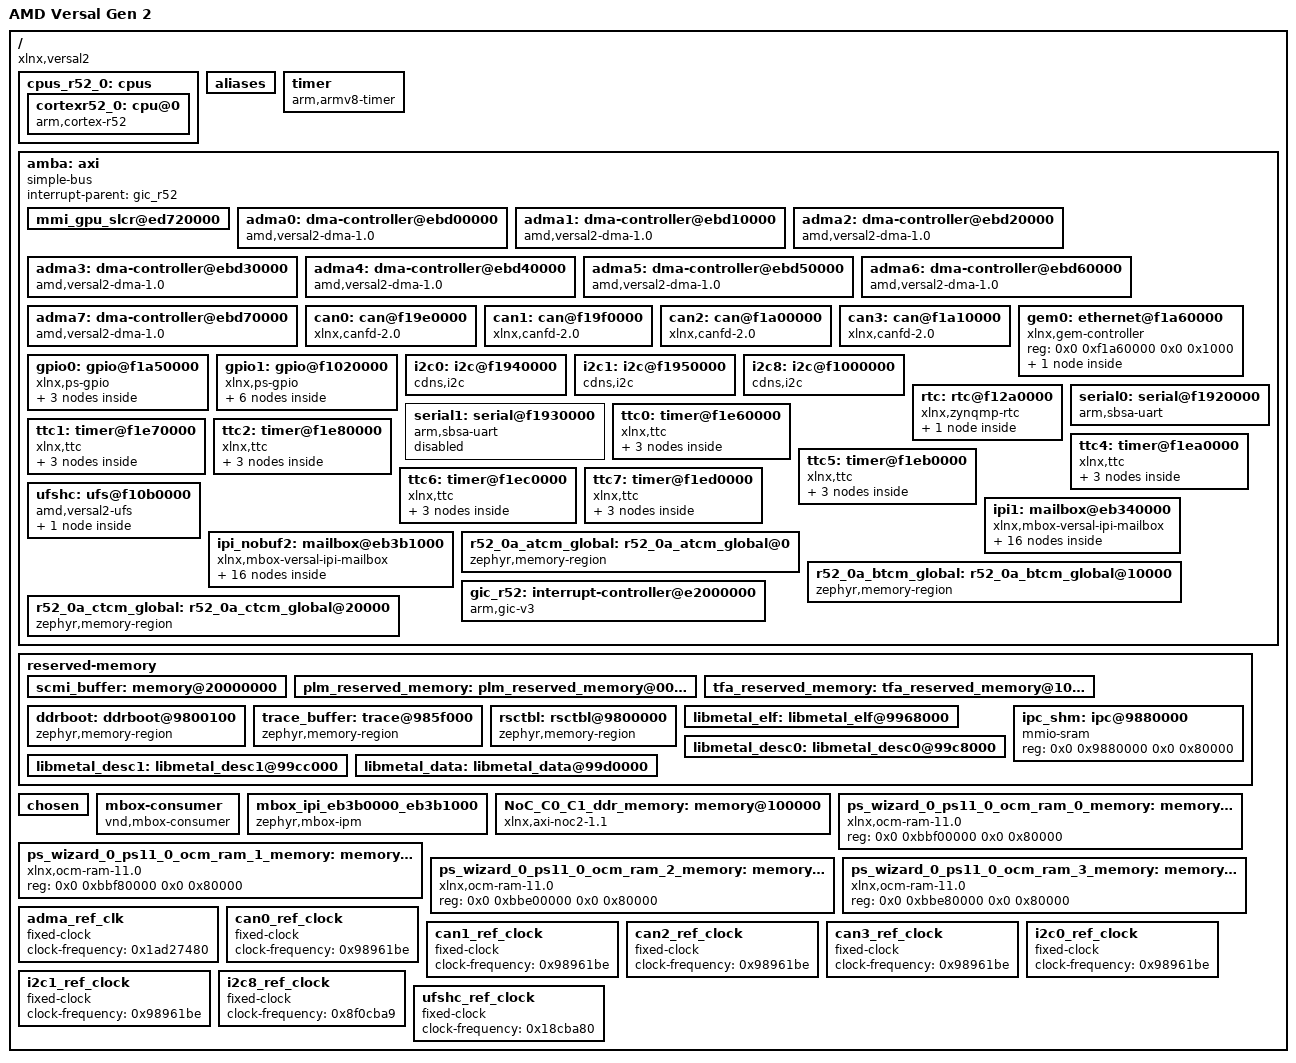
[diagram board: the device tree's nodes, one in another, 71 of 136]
/dts-v1/;
/ {
        compatible = "xlnx,versal2";
        model = "AMD Versal Gen 2";
        #address-cells = <0x2>;
        #size-cells = <0x2>;
        interrupt-parent = <&gic_r52>;
        board = "vek386";
        vivado-version = "2026.2.0";
        device_id = "xc2ve3858";
        xlnx,ddrmc5-debug-elf = "false";
        xlnx,ddrmc5-i2c-master = "PMC";
        slrcount = <0x1>;
        family = "Versal_2VE_2VM";
        speed_grade = "2MP";
        pruned-sdt = <0x1>;

        cpus_r52_0: cpus {
                phandle = <0x12a>;
                #address-cells = <0x1>;
                #size-cells = <0x0>;

                cortexr52_0: cpu@0 {
                        phandle = <0x12b>;
                        compatible = "arm,cortex-r52";
                        device_type = "cpu";
                        reg = <0x0>;
                        clock-frequency = <0x5f5dd19>;
                };
        };

        aliases {
                serial0 = "/axi/serial@f1920000";
                serial1 = "/axi/serial@f1930000";
                i2c0 = "/axi/i2c@f1000000";
                i2c1 = "/axi/i2c@f1940000";
                i2c2 = "/axi/i2c@f1950000";
                i2c8 = "/axi/i2c@f1000000";
                ethernet0 = "/axi/ethernet@f1a60000";
                ufs0 = "/axi/ufs@f10b0000";
                rtc = "/axi/rtc@f12a0000/rtc-counter";
        };

        timer: timer {
                phandle = <0x156>;
                compatible = "arm,armv8-timer";
                interrupts = <0x1 0xd 0x4 0xa4 0x1 0xe 0x4 0xa4 0x1 0xb 0x4 0xa4 0x1 0xa 0x4 0xa4>;
        };

        amba: axi {
                phandle = <0x2>;
                compatible = "simple-bus";
                bootph-all;
                #address-cells = <0x2>;
                #size-cells = <0x2>;
                ranges;
                interrupt-parent = <&gic_r52>;

                mmi_gpu_slcr@ed720000 {
                        reg = <0x0 0xed720000 0x0 0x20000>;
                        no-map;
                };

                adma0: dma-controller@ebd00000 {
                        phandle = <0x48>;
                        compatible = "amd,versal2-dma-1.0";
                        reg = <0x0 0xebd00000 0x0 0x1000>;
                        interrupts = <0x0 0x48 0x4 0xa0>;
                        clock-names = "clk_main", "clk_apb";
                        #dma-cells = <0x1>;
                        clocks = <&adma_ref_clk>,
                         <&adma_ref_clk>;
                };

                adma1: dma-controller@ebd10000 {
                        phandle = <0x49>;
                        compatible = "amd,versal2-dma-1.0";
                        reg = <0x0 0xebd10000 0x0 0x1000>;
                        interrupts = <0x0 0x49 0x4 0xa0>;
                        clock-names = "clk_main", "clk_apb";
                        #dma-cells = <0x1>;
                        clocks = <&adma_ref_clk>,
                         <&adma_ref_clk>;
                };

                adma2: dma-controller@ebd20000 {
                        phandle = <0x4a>;
                        compatible = "amd,versal2-dma-1.0";
                        reg = <0x0 0xebd20000 0x0 0x1000>;
                        interrupts = <0x0 0x4a 0x4 0xa0>;
                        clock-names = "clk_main", "clk_apb";
                        #dma-cells = <0x1>;
                        clocks = <&adma_ref_clk>,
                         <&adma_ref_clk>;
                };

                adma3: dma-controller@ebd30000 {
                        phandle = <0x4b>;
                        compatible = "amd,versal2-dma-1.0";
                        reg = <0x0 0xebd30000 0x0 0x1000>;
                        interrupts = <0x0 0x4b 0x4 0xa0>;
                        clock-names = "clk_main", "clk_apb";
                        #dma-cells = <0x1>;
                        clocks = <&adma_ref_clk>,
                         <&adma_ref_clk>;
                };

                adma4: dma-controller@ebd40000 {
                        phandle = <0x4c>;
                        compatible = "amd,versal2-dma-1.0";
                        reg = <0x0 0xebd40000 0x0 0x1000>;
                        interrupts = <0x0 0x4c 0x4 0xa0>;
                        clock-names = "clk_main", "clk_apb";
                        #dma-cells = <0x1>;
                        clocks = <&adma_ref_clk>,
                         <&adma_ref_clk>;
                };

                adma5: dma-controller@ebd50000 {
                        phandle = <0x4d>;
                        compatible = "amd,versal2-dma-1.0";
                        reg = <0x0 0xebd50000 0x0 0x1000>;
                        interrupts = <0x0 0x4d 0x4 0xa0>;
                        clock-names = "clk_main", "clk_apb";
                        #dma-cells = <0x1>;
                        clocks = <&adma_ref_clk>,
                         <&adma_ref_clk>;
                };

                adma6: dma-controller@ebd60000 {
                        phandle = <0x4e>;
                        compatible = "amd,versal2-dma-1.0";
                        reg = <0x0 0xebd60000 0x0 0x1000>;
                        interrupts = <0x0 0x4e 0x4 0xa0>;
                        clock-names = "clk_main", "clk_apb";
                        #dma-cells = <0x1>;
                        clocks = <&adma_ref_clk>,
                         <&adma_ref_clk>;
                };

                adma7: dma-controller@ebd70000 {
                        phandle = <0x4f>;
                        compatible = "amd,versal2-dma-1.0";
                        reg = <0x0 0xebd70000 0x0 0x1000>;
                        interrupts = <0x0 0x4f 0x4 0xa0>;
                        clock-names = "clk_main", "clk_apb";
                        #dma-cells = <0x1>;
                        clocks = <&adma_ref_clk>,
                         <&adma_ref_clk>;
                };

                can0: can@f19e0000 {
                        phandle = <0xa5>;
                        compatible = "xlnx,canfd-2.0";
                        reg = <0x0 0xf19e0000 0x0 0x6000>;
                        interrupts = <0x0 0x1b 0x4 0xa0>;
                        clocks = <&can0_ref_clock>;
                };

                can1: can@f19f0000 {
                        phandle = <0xa6>;
                        compatible = "xlnx,canfd-2.0";
                        reg = <0x0 0xf19f0000 0x0 0x6000>;
                        interrupts = <0x0 0x1c 0x4 0xa0>;
                        clocks = <&can1_ref_clock>;
                };

                can2: can@f1a00000 {
                        phandle = <0xa7>;
                        compatible = "xlnx,canfd-2.0";
                        reg = <0x0 0xf1a00000 0x0 0x6000>;
                        interrupts = <0x0 0x5f 0x4 0xa0>;
                        clocks = <&can2_ref_clock>;
                };

                can3: can@f1a10000 {
                        phandle = <0xa8>;
                        compatible = "xlnx,canfd-2.0";
                        reg = <0x0 0xf1a10000 0x0 0x6000>;
                        interrupts = <0x0 0x60 0x4 0xa0>;
                        clocks = <&can3_ref_clock>;
                };

                gem0: ethernet@f1a60000 {
                        phandle = <0xac>;
                        compatible = "xlnx,gem-controller";
                        status = "okay";
                        reg = <0x0 0xf1a60000 0x0 0x1000>;

                        gem0_mac: ethernet_mac {
                                phandle = <0xc>;
                                compatible = "xlnx,gem";
                                status = "okay";
                                clock-frequency = <0x7735464>;
                                interrupts = <0x0 0x27 0x4 0xa0 0x0 0x27 0x4 0xa0>;
                                amba-ahb-burst-length = <0x10>;
                                hw-rx-buffer-size = <0x3>;
                                hw-rx-buffer-offset = <0x0>;
                                hw-tx-buffer-size-full;
                                rx-buffer-descriptors = <0x20>;
                                tx-buffer-descriptors = <0x20>;
                                rx-buffer-size = <0x600>;
                                tx-buffer-size = <0x600>;
                                discard-rx-fcs;
                                unicast-hash;
                                local-mac-address = [00 0A 35 00 01 02];
                        };
                };

                gpio0: gpio@f1a50000 {
                        phandle = <0xab>;
                        compatible = "xlnx,ps-gpio";
                        reg = <0x0 0xf1a50000 0x0 0x1000>;
                        interrupts = <0x0 0x14 0x4 0xa0>;
                        #address-cells = <0x1>;
                        #size-cells = <0x0>;

                        gpio0_bank0: gpio0_bank@0 {
                                phandle = <0xd>;
                                compatible = "xlnx,ps-gpio-bank";
                                reg = <0x0>;
                                #gpio-cells = <0x2>;
                                gpio-controller;
                                ngpios = <0x1a>;
                        };

                        gpio0_bank3: gpio0_bank@3 {
                                phandle = <0x12>;
                                compatible = "xlnx,ps-gpio-bank";
                                reg = <0x3>;
                                #gpio-cells = <0x2>;
                                gpio-controller;
                                ngpios = <0x20>;
                        };

                        gpio0_bank4: gpio0_bank@4 {
                                phandle = <0x13>;
                                compatible = "xlnx,ps-gpio-bank";
                                reg = <0x4>;
                                #gpio-cells = <0x2>;
                                gpio-controller;
                                ngpios = <0x20>;
                        };
                };

                gpio1: gpio@f1020000 {
                        phandle = <0x89>;
                        compatible = "xlnx,ps-gpio";
                        reg = <0x0 0xf1020000 0x0 0x1000>;
                        interrupts = <0x0 0xca 0x4 0xa0>;
                        #address-cells = <0x1>;
                        #size-cells = <0x0>;

                        gpio1_bank0: gpio1_bank@0 {
                                phandle = <0x14>;
                                compatible = "xlnx,ps-gpio-bank";
                                reg = <0x0>;
                                #gpio-cells = <0x2>;
                                gpio-controller;
                                ngpios = <0x1a>;
                        };

                        gpio1_bank1: gpio1_bank@1 {
                                phandle = <0x15>;
                                compatible = "xlnx,ps-gpio-bank";
                                reg = <0x1>;
                                #gpio-cells = <0x2>;
                                gpio-controller;
                                ngpios = <0x1a>;
                        };

                        gpio1_bank3: gpio1_bank@3 {
                                phandle = <0x16>;
                                compatible = "xlnx,ps-gpio-bank";
                                reg = <0x3>;
                                #gpio-cells = <0x2>;
                                gpio-controller;
                                ngpios = <0x20>;
                        };

                        gpio1_bank4: gpio1_bank@4 {
                                phandle = <0x17>;
                                compatible = "xlnx,ps-gpio-bank";
                                reg = <0x4>;
                                #gpio-cells = <0x2>;
                                gpio-controller;
                                ngpios = <0x20>;
                        };

                        gpio1_bank2: gpio1_bank@2 {
                                phandle = <0x18>;
                                compatible = "xlnx,ps-gpio-bank";
                                reg = <0x2>;
                                #gpio-cells = <0x2>;
                                gpio-controller;
                                ngpios = <0x1a>;
                        };

                        gpio1_bank5: gpio1_bank@5 {
                                phandle = <0x19>;
                                compatible = "xlnx,ps-gpio-bank";
                                reg = <0x5>;
                                #gpio-cells = <0x2>;
                                gpio-controller;
                                ngpios = <0x20>;
                        };
                };

                i2c0: i2c@f1940000 {
                        phandle = <0xa3>;
                        compatible = "cdns,i2c";
                        status = "okay";
                        reg = <0x0 0xf1940000 0x0 0x1000>;
                        interrupt-parent = <&gic_r52>;
                        interrupts = <0x0 0x15 0x4 0xa0>;
                        clock-frequency = <0x186a0>;
                        fifo-depth = <0x10>;
                        #address-cells = <0x1>;
                        #size-cells = <0x0>;
                        clocks = <&i2c0_ref_clock>;
                };

                i2c1: i2c@f1950000 {
                        phandle = <0xa4>;
                        compatible = "cdns,i2c";
                        status = "okay";
                        reg = <0x0 0xf1950000 0x0 0x1000>;
                        interrupt-parent = <&gic_r52>;
                        interrupts = <0x0 0x16 0x4 0xa0>;
                        #address-cells = <0x1>;
                        #size-cells = <0x0>;
                        clock-frequency = <0x61a80>;
                        fifo-depth = <0x10>;
                        clocks = <&i2c1_ref_clock>;
                };

                i2c8: i2c@f1000000 {
                        phandle = <0x87>;
                        compatible = "cdns,i2c";
                        status = "okay";
                        reg = <0x0 0xf1000000 0x0 0x1000>;
                        interrupt-parent = <&gic_r52>;
                        interrupts = <0x0 0xcb 0x4 0xa0>;
                        #address-cells = <0x1>;
                        #size-cells = <0x0>;
                        clock-frequency = <0x61a80>;
                        fifo-depth = <0x10>;
                        clocks = <&i2c8_ref_clock>;
                };

                rtc: rtc@f12a0000 {
                        phandle = <0x9a>;
                        compatible = "xlnx,zynqmp-rtc";
                        status = "okay";
                        reg = <0x0 0xf12a0000 0x0 0x100>;
                        interrupt-parent = <&gic_r52>;
                        interrupts = <0x0 0xc8 0x4 0xa0 0x0 0xc9 0x4 0xa0>;
                        interrupt-names = "alarm", "sec";
                        clock-frequency = <0x8000>;

                        rtc-counter {
                                compatible = "zephyr,rtc-counter";
                                status = "okay";
                                alarms-count = <0x1>;
                        };
                };

                serial0: serial@f1920000 {
                        phandle = <0xa1>;
                        compatible = "arm,sbsa-uart";
                        status = "okay";
                        reg = <0x0 0xf1920000 0x0 0x1000>;
                        interrupt-parent = <&gic_r52>;
                        interrupts = <0x0 0x19 0x4 0xa0>;
                        interrupt-names = "serial0";
                };

                serial1: serial@f1930000 {
                        phandle = <0xa2>;
                        compatible = "arm,sbsa-uart";
                        status = "disabled";
                        reg = <0x0 0xf1930000 0x0 0x1000>;
                        interrupt-parent = <&gic_r52>;
                        interrupts = <0x0 0x1a 0x4 0xa0>;
                        interrupt-names = "serial1";
                };

                ttc0: timer@f1e60000 {
                        phandle = <0xae>;
                        compatible = "xlnx,ttc";
                        status = "okay";
                        timer-width = <0x20>;
                        reg = <0x0 0xf1e60000 0x0 0x1000>;
                        clock-frequency = <0x8f0cba9>;
                        #address-cells = <0x1>;
                        #size-cells = <0x0>;

                        ttc0_timer0: counter@0 {
                                phandle = <0x1a>;
                                compatible = "xlnx,ttc-counter";
                                reg = <0x0>;
                                interrupts = <0x0 0x2b 0x4 0xa0>;
                        };

                        ttc0_timer1: counter@1 {
                                phandle = <0x1b>;
                                compatible = "xlnx,ttc-counter";
                                reg = <0x1>;
                                interrupts = <0x0 0x2b 0x4 0xa0>;
                        };

                        ttc0_timer2: counter@2 {
                                phandle = <0x1c>;
                                compatible = "xlnx,ttc-counter";
                                reg = <0x2>;
                                interrupts = <0x0 0x2b 0x4 0xa0>;
                        };
                };

                ttc1: timer@f1e70000 {
                        phandle = <0xaf>;
                        compatible = "xlnx,ttc";
                        status = "okay";
                        timer-width = <0x20>;
                        reg = <0x0 0xf1e70000 0x0 0x1000>;
                        clock-frequency = <0x8f0cba9>;
                        #address-cells = <0x1>;
                        #size-cells = <0x0>;

                        ttc1_timer0: counter@0 {
                                phandle = <0x1d>;
                                compatible = "xlnx,ttc-counter";
                                reg = <0x0>;
                                interrupts = <0x0 0x2c 0x4 0xa0>;
                        };

                        ttc1_timer1: counter@1 {
                                phandle = <0x1e>;
                                compatible = "xlnx,ttc-counter";
                                reg = <0x1>;
                                interrupts = <0x0 0x2c 0x4 0xa0>;
                        };

                        ttc1_timer2: counter@2 {
                                phandle = <0x1f>;
                                compatible = "xlnx,ttc-counter";
                                reg = <0x2>;
                                interrupts = <0x0 0x2c 0x4 0xa0>;
                        };
                };

                ttc2: timer@f1e80000 {
                        phandle = <0xb0>;
                        compatible = "xlnx,ttc";
                        status = "okay";
                        timer-width = <0x20>;
                        reg = <0x0 0xf1e80000 0x0 0x1000>;
                        clock-frequency = <0x8f0cba9>;
                        #address-cells = <0x1>;
                        #size-cells = <0x0>;

                        ttc2_timer0: counter@0 {
                                phandle = <0x20>;
                                compatible = "xlnx,ttc-counter";
                                reg = <0x0>;
                                interrupts = <0x0 0x2d 0x4 0xa0>;
                        };

                        ttc2_timer1: counter@1 {
                                phandle = <0x21>;
                                compatible = "xlnx,ttc-counter";
                                reg = <0x1>;
                                interrupts = <0x0 0x2d 0x4 0xa0>;
                        };

                        ttc2_timer2: counter@2 {
                                phandle = <0x22>;
                                compatible = "xlnx,ttc-counter";
                                reg = <0x2>;
                                interrupts = <0x0 0x2d 0x4 0xa0>;
                        };
                };

                ttc4: timer@f1ea0000 {
                        phandle = <0xb2>;
                        compatible = "xlnx,ttc";
                        status = "okay";
                        timer-width = <0x20>;
                        reg = <0x0 0xf1ea0000 0x0 0x1000>;
                        clock-frequency = <0x8f0cba9>;
                        #address-cells = <0x1>;
                        #size-cells = <0x0>;

                        ttc4_timer0: counter@0 {
                                phandle = <0x23>;
                                compatible = "xlnx,ttc-counter";
                                reg = <0x0>;
                                interrupts = <0x0 0x2f 0x4 0xa0>;
                        };

                        ttc4_timer1: counter@1 {
                                phandle = <0x24>;
                                compatible = "xlnx,ttc-counter";
                                reg = <0x1>;
                                interrupts = <0x0 0x2f 0x4 0xa0>;
                        };

                        ttc4_timer2: counter@2 {
                                phandle = <0x25>;
                                compatible = "xlnx,ttc-counter";
                                reg = <0x2>;
                                interrupts = <0x0 0x2f 0x4 0xa0>;
                        };
                };

                ttc5: timer@f1eb0000 {
                        phandle = <0xb3>;
                        compatible = "xlnx,ttc";
                        status = "okay";
                        timer-width = <0x20>;
                        reg = <0x0 0xf1eb0000 0x0 0x1000>;
                        clock-frequency = <0x8f0cba9>;
                        #address-cells = <0x1>;
                        #size-cells = <0x0>;

                        ttc5_timer0: counter@0 {
                                phandle = <0x26>;
                                compatible = "xlnx,ttc-counter";
                                reg = <0x0>;
                                interrupts = <0x0 0x30 0x4 0xa0>;
                        };

                        ttc5_timer1: counter@1 {
                                phandle = <0x27>;
                                compatible = "xlnx,ttc-counter";
                                reg = <0x1>;
                                interrupts = <0x0 0x30 0x4 0xa0>;
                        };

                        ttc5_timer2: counter@2 {
                                phandle = <0x28>;
                                compatible = "xlnx,ttc-counter";
                                reg = <0x2>;
                                interrupts = <0x0 0x30 0x4 0xa0>;
                        };
                };

                ttc6: timer@f1ec0000 {
                        phandle = <0xb4>;
                        compatible = "xlnx,ttc";
                        status = "okay";
                        timer-width = <0x20>;
                        reg = <0x0 0xf1ec0000 0x0 0x1000>;
                        clock-frequency = <0x8f0cba9>;
                        #address-cells = <0x1>;
                        #size-cells = <0x0>;

                        ttc6_timer0: counter@0 {
                                phandle = <0x29>;
                                compatible = "xlnx,ttc-counter";
                                reg = <0x0>;
                                interrupts = <0x0 0x31 0x4 0xa0>;
                        };

                        ttc6_timer1: counter@1 {
                                phandle = <0x2d>;
                                compatible = "xlnx,ttc-counter";
                                reg = <0x1>;
                                interrupts = <0x0 0x31 0x4 0xa0>;
                        };

                        ttc6_timer2: counter@2 {
                                phandle = <0x2e>;
                                compatible = "xlnx,ttc-counter";
                                reg = <0x2>;
                                interrupts = <0x0 0x31 0x4 0xa0>;
                        };
                };

                ttc7: timer@f1ed0000 {
                        phandle = <0xb5>;
                        compatible = "xlnx,ttc";
                        status = "okay";
                        timer-width = <0x20>;
                        reg = <0x0 0xf1ed0000 0x0 0x1000>;
                        clock-frequency = <0x8f0cba9>;
                        #address-cells = <0x1>;
                        #size-cells = <0x0>;

                        ttc7_timer0: counter@0 {
                                phandle = <0x2f>;
                                compatible = "xlnx,ttc-counter";
                                reg = <0x0>;
                                interrupts = <0x0 0x32 0x4 0xa0>;
                        };

                        ttc7_timer1: counter@1 {
                                phandle = <0x30>;
                                compatible = "xlnx,ttc-counter";
                                reg = <0x1>;
                                interrupts = <0x0 0x32 0x4 0xa0>;
                        };

                        ttc7_timer2: counter@2 {
                                phandle = <0x31>;
                                compatible = "xlnx,ttc-counter";
                                reg = <0x2>;
                                interrupts = <0x0 0x32 0x4 0xa0>;
                        };
                };

                ufshc: ufs@f10b0000 {
                        phandle = <0x8b>;
                        compatible = "amd,versal2-ufs";
                        status = "okay";
                        interrupt-parent = <&gic_r52>;
                        interrupts = <0x0 0xea 0x4 0xa0>;
                        reg = <0x0 0xf10b0000 0x0 0x100 0x0 0xf1060000 0x0 0x2000 0x0 0xf1250000 0x0 0x10000 0x0 0xf1260000 0x0 0x10000>;
                        clock-names = "core", "ref_clk";
                        clocks = <&ufshc_ref_clock>,
                         <&ufshc_ref_clock>;

                        ufsdisk0 {
                                compatible = "zephyr,ufs-disk";
                                disk-name = "UFS";
                        };
                };

                ipi1: mailbox@eb340000 {
                        phandle = <0xd5>;
                        compatible = "xlnx,mbox-versal-ipi-mailbox";
                        interrupt-parent = <&gic_r52>;
                        interrupts = <0x0 0x3a 0x4 0xa0>;
                        reg = <0x0 0xeb340000 0x0 0x10000 0x0 0xeb3f0600 0x0 0x200>;
                        xlnx,ipi-id = <0x3>;
                        #address-cells = <0x2>;
                        #size-cells = <0x2>;
                        reg-names = "ctrl", "msg";

                        ipi_1_to_ipi_asu: child@eb310000 {
                                phandle = <0x19d>;
                                compatible = "xlnx,mbox-versal-ipi-dest-mailbox";
                                #mbox-cells = <0x1>;
                                xlnx,ipi-id = <0x0>;
                                reg = <0x0 0xeb310000 0x0 0x10000 0x0 0xeb3f0000 0x0 0x200>;
                                reg-names = "ctrl", "msg";
                        };

                        ipi_1_to_ipi_0: child@eb330000 {
                                phandle = <0x19e>;
                                compatible = "xlnx,mbox-versal-ipi-dest-mailbox";
                                #mbox-cells = <0x1>;
                                xlnx,ipi-id = <0x2>;
                                reg = <0x0 0xeb330000 0x0 0x10000 0x0 0xeb3f0400 0x0 0x200>;
                                reg-names = "ctrl", "msg";
                        };

                        ipi_1_to_ipi_1: child@eb340000 {
                                phandle = <0x19f>;
                                compatible = "xlnx,mbox-versal-ipi-dest-mailbox";
                                #mbox-cells = <0x1>;
                                xlnx,ipi-id = <0x3>;
                                reg = <0x0 0xeb340000 0x0 0x10000 0x0 0xeb3f0600 0x0 0x200>;
                                reg-names = "ctrl", "msg";
                        };

                        ipi_1_to_ipi_1_nobuf: child@eb3b0000 {
                                phandle = <0x1a0>;
                                compatible = "xlnx,mbox-versal-ipi-dest-mailbox";
                                #mbox-cells = <0x1>;
                                xlnx,ipi-id = <0xa>;
                                reg = <0x0 0xeb3b0000 0x0 0x1000>;
                                reg-names = "ctrl";
                        };

                        ipi_1_to_ipi_2: child@eb350000 {
                                phandle = <0x1a1>;
                                compatible = "xlnx,mbox-versal-ipi-dest-mailbox";
                                #mbox-cells = <0x1>;
                                xlnx,ipi-id = <0x4>;
                                reg = <0x0 0xeb350000 0x0 0x10000 0x0 0xeb3f0800 0x0 0x200>;
                                reg-names = "ctrl", "msg";
                        };

                        ipi_1_to_ipi_2_nobuf: child@eb3b1000 {
                                phandle = <0x1a2>;
                                compatible = "xlnx,mbox-versal-ipi-dest-mailbox";
                                #mbox-cells = <0x1>;
                                xlnx,ipi-id = <0xb>;
                                reg = <0x0 0xeb3b1000 0x0 0x1000>;
                                reg-names = "ctrl";
                        };

                        ipi_1_to_ipi_3: child@eb360000 {
                                phandle = <0x1a3>;
                                compatible = "xlnx,mbox-versal-ipi-dest-mailbox";
                                #mbox-cells = <0x1>;
                                xlnx,ipi-id = <0x5>;
                                reg = <0x0 0xeb360000 0x0 0x10000 0x0 0xeb3f0a00 0x0 0x200>;
                                reg-names = "ctrl", "msg";
                        };

                        ipi_1_to_ipi_3_nobuf: child@eb3b2000 {
                                phandle = <0x1a4>;
                                compatible = "xlnx,mbox-versal-ipi-dest-mailbox";
                                #mbox-cells = <0x1>;
                                xlnx,ipi-id = <0xc>;
                                reg = <0x0 0xeb3b2000 0x0 0x1000>;
                                reg-names = "ctrl";
                        };

                        ipi_1_to_ipi_4: child@eb370000 {
                                phandle = <0x1a5>;
                                compatible = "xlnx,mbox-versal-ipi-dest-mailbox";
                                #mbox-cells = <0x1>;
                                xlnx,ipi-id = <0x6>;
                                reg = <0x0 0xeb370000 0x0 0x10000 0x0 0xeb3f0c00 0x0 0x200>;
                                reg-names = "ctrl", "msg";
                        };

                        ipi_1_to_ipi_4_nobuf: child@eb3b3000 {
                                phandle = <0x1a6>;
                                compatible = "xlnx,mbox-versal-ipi-dest-mailbox";
                                #mbox-cells = <0x1>;
                                xlnx,ipi-id = <0xd>;
                                reg = <0x0 0xeb3b3000 0x0 0x1000>;
                                reg-names = "ctrl";
                        };

                        ipi_1_to_ipi_5: child@eb380000 {
                                phandle = <0x1a7>;
                                compatible = "xlnx,mbox-versal-ipi-dest-mailbox";
                                #mbox-cells = <0x1>;
                                xlnx,ipi-id = <0x7>;
                                reg = <0x0 0xeb380000 0x0 0x10000 0x0 0xeb3f0e00 0x0 0x200>;
                                reg-names = "ctrl", "msg";
                        };

                        ipi_1_to_ipi_5_nobuf: child@eb3b4000 {
                                phandle = <0x1a8>;
                                compatible = "xlnx,mbox-versal-ipi-dest-mailbox";
                                #mbox-cells = <0x1>;
                                xlnx,ipi-id = <0xe>;
                                reg = <0x0 0xeb3b4000 0x0 0x1000>;
                                reg-names = "ctrl";
                        };

                        ipi_1_to_ipi_6: child@eb3a0000 {
                                phandle = <0x1a9>;
                                compatible = "xlnx,mbox-versal-ipi-dest-mailbox";
                                #mbox-cells = <0x1>;
                                xlnx,ipi-id = <0x9>;
                                reg = <0x0 0xeb3a0000 0x0 0x10000>;
                                reg-names = "ctrl";
                        };

                        ipi_1_to_ipi_6_nobuf: child@eb3b5000 {
                                phandle = <0x1aa>;
                                compatible = "xlnx,mbox-versal-ipi-dest-mailbox";
                                #mbox-cells = <0x1>;
                                xlnx,ipi-id = <0xf>;
                                reg = <0x0 0xeb3b5000 0x0 0x1000>;
                                reg-names = "ctrl";
                        };

                        ipi_1_to_ipi_pmc: child@eb320000 {
                                phandle = <0x1ab>;
                                compatible = "xlnx,mbox-versal-ipi-dest-mailbox";
                                #mbox-cells = <0x1>;
                                xlnx,ipi-id = <0x1>;
                                reg = <0x0 0xeb320000 0x0 0x10000 0x0 0xeb3f0200 0x0 0x200>;
                                reg-names = "ctrl", "msg";
                        };

                        ipi_1_to_ipi_pmc_nobuf: child@eb390000 {
                                phandle = <0x1ac>;
                                compatible = "xlnx,mbox-versal-ipi-dest-mailbox";
                                #mbox-cells = <0x1>;
                                xlnx,ipi-id = <0x8>;
                                reg = <0x0 0xeb390000 0x0 0x10000>;
                                reg-names = "ctrl";
                        };
                };

                ipi_nobuf2: mailbox@eb3b1000 {
                        phandle = <0xd6>;
                        compatible = "xlnx,mbox-versal-ipi-mailbox";
                        interrupt-parent = <&gic_r52>;
                        interrupts = <0x0 0x41 0x4 0xa0>;
                        reg = <0x0 0xeb3b1000 0x0 0x1000>;
                        xlnx,ipi-id = <0xb>;
                        #address-cells = <0x2>;
                        #size-cells = <0x2>;
                        reg-names = "ctrl";

                        ipi_2_nobuf_to_ipi_asu: child@eb310000 {
                                phandle = <0x20d>;
                                compatible = "xlnx,mbox-versal-ipi-dest-mailbox";
                                #mbox-cells = <0x1>;
                                xlnx,ipi-id = <0x0>;
                                reg = <0x0 0xeb310000 0x0 0x10000 0x0 0xeb3f0000 0x0 0x200>;
                                reg-names = "ctrl", "msg";
                        };

                        ipi_2_nobuf_to_ipi_0: child@eb330000 {
                                phandle = <0x20e>;
                                compatible = "xlnx,mbox-versal-ipi-dest-mailbox";
                                #mbox-cells = <0x1>;
                                xlnx,ipi-id = <0x2>;
                                reg = <0x0 0xeb330000 0x0 0x10000 0x0 0xeb3f0400 0x0 0x200>;
                                reg-names = "ctrl", "msg";
                        };

                        ipi_2_nobuf_to_ipi_1: child@eb340000 {
                                phandle = <0x20f>;
                                compatible = "xlnx,mbox-versal-ipi-dest-mailbox";
                                #mbox-cells = <0x1>;
                                xlnx,ipi-id = <0x3>;
                                reg = <0x0 0xeb340000 0x0 0x10000 0x0 0xeb3f0600 0x0 0x200>;
                                reg-names = "ctrl", "msg";
                        };

                        ipi_2_nobuf_to_ipi_1_nobuf: child@eb3b0000 {
                                phandle = <0x210>;
                                compatible = "xlnx,mbox-versal-ipi-dest-mailbox";
                                #mbox-cells = <0x1>;
                                xlnx,ipi-id = <0xa>;
                                reg = <0x0 0xeb3b0000 0x0 0x1000>;
                                reg-names = "ctrl";
                        };

                        ipi_2_nobuf_to_ipi_2: child@eb350000 {
                                phandle = <0x211>;
                                compatible = "xlnx,mbox-versal-ipi-dest-mailbox";
                                #mbox-cells = <0x1>;
                                xlnx,ipi-id = <0x4>;
                                reg = <0x0 0xeb350000 0x0 0x10000 0x0 0xeb3f0800 0x0 0x200>;
                                reg-names = "ctrl", "msg";
                        };

                        ipi_2_nobuf_to_ipi_2_nobuf: child@eb3b1000 {
                                phandle = <0x212>;
                                compatible = "xlnx,mbox-versal-ipi-dest-mailbox";
                                #mbox-cells = <0x1>;
                                xlnx,ipi-id = <0xb>;
                                reg = <0x0 0xeb3b1000 0x0 0x1000>;
                                reg-names = "ctrl";
                        };

                        ipi_2_nobuf_to_ipi_3: child@eb360000 {
                                phandle = <0x213>;
                                compatible = "xlnx,mbox-versal-ipi-dest-mailbox";
                                #mbox-cells = <0x1>;
                                xlnx,ipi-id = <0x5>;
                                reg = <0x0 0xeb360000 0x0 0x10000 0x0 0xeb3f0a00 0x0 0x200>;
                                reg-names = "ctrl", "msg";
                        };

                        ipi_2_nobuf_to_ipi_3_nobuf: child@eb3b2000 {
                                phandle = <0x214>;
                                compatible = "xlnx,mbox-versal-ipi-dest-mailbox";
                                #mbox-cells = <0x1>;
                                xlnx,ipi-id = <0xc>;
                                reg = <0x0 0xeb3b2000 0x0 0x1000>;
                                reg-names = "ctrl";
                        };

                        ipi_2_nobuf_to_ipi_4: child@eb370000 {
                                phandle = <0x215>;
                                compatible = "xlnx,mbox-versal-ipi-dest-mailbox";
                                #mbox-cells = <0x1>;
                                xlnx,ipi-id = <0x6>;
                                reg = <0x0 0xeb370000 0x0 0x10000 0x0 0xeb3f0c00 0x0 0x200>;
                                reg-names = "ctrl", "msg";
                        };

                        ipi_2_nobuf_to_ipi_4_nobuf: child@eb3b3000 {
                                phandle = <0x216>;
                                compatible = "xlnx,mbox-versal-ipi-dest-mailbox";
                                #mbox-cells = <0x1>;
                                xlnx,ipi-id = <0xd>;
                                reg = <0x0 0xeb3b3000 0x0 0x1000>;
                                reg-names = "ctrl";
                        };

                        ipi_2_nobuf_to_ipi_5: child@eb380000 {
                                phandle = <0x217>;
                                compatible = "xlnx,mbox-versal-ipi-dest-mailbox";
                                #mbox-cells = <0x1>;
                                xlnx,ipi-id = <0x7>;
                                reg = <0x0 0xeb380000 0x0 0x10000 0x0 0xeb3f0e00 0x0 0x200>;
                                reg-names = "ctrl", "msg";
                        };

                        ipi_2_nobuf_to_ipi_5_nobuf: child@eb3b4000 {
                                phandle = <0x218>;
                                compatible = "xlnx,mbox-versal-ipi-dest-mailbox";
                                #mbox-cells = <0x1>;
                                xlnx,ipi-id = <0xe>;
                                reg = <0x0 0xeb3b4000 0x0 0x1000>;
                                reg-names = "ctrl";
                        };

                        ipi_2_nobuf_to_ipi_6: child@eb3a0000 {
                                phandle = <0x219>;
                                compatible = "xlnx,mbox-versal-ipi-dest-mailbox";
                                #mbox-cells = <0x1>;
                                xlnx,ipi-id = <0x9>;
                                reg = <0x0 0xeb3a0000 0x0 0x10000>;
                                reg-names = "ctrl";
                        };

                        ipi_2_nobuf_to_ipi_6_nobuf: child@eb3b5000 {
                                phandle = <0x21a>;
                                compatible = "xlnx,mbox-versal-ipi-dest-mailbox";
                                #mbox-cells = <0x1>;
                                xlnx,ipi-id = <0xf>;
                                reg = <0x0 0xeb3b5000 0x0 0x1000>;
                                reg-names = "ctrl";
                        };

                        ipi_2_nobuf_to_ipi_pmc: child@eb320000 {
                                phandle = <0x21b>;
                                compatible = "xlnx,mbox-versal-ipi-dest-mailbox";
                                #mbox-cells = <0x1>;
                                xlnx,ipi-id = <0x1>;
                                reg = <0x0 0xeb320000 0x0 0x10000 0x0 0xeb3f0200 0x0 0x200>;
                                reg-names = "ctrl", "msg";
                        };

                        ipi_2_nobuf_to_ipi_pmc_nobuf: child@eb390000 {
                                phandle = <0x21c>;
                                compatible = "xlnx,mbox-versal-ipi-dest-mailbox";
                                #mbox-cells = <0x1>;
                                xlnx,ipi-id = <0x8>;
                                reg = <0x0 0xeb390000 0x0 0x10000>;
                                reg-names = "ctrl";
                        };
                };

                r52_0a_atcm_global: r52_0a_atcm_global@0 {
                        phandle = <0x2a>;
                        status = "okay";
                        compatible = "zephyr,memory-region", "xlnx,tcm";
                        reg = <0x0 0x0 0x0 0x10000>;
                        zephyr,memory-region = "R52_0A_ATCM_GLOBAL";
                };

                r52_0a_btcm_global: r52_0a_btcm_global@10000 {
                        phandle = <0x2b>;
                        status = "okay";
                        compatible = "zephyr,memory-region", "xlnx,tcm";
                        reg = <0x0 0x10000 0x0 0x8000>;
                        zephyr,memory-region = "R52_0A_BTCM_GLOBAL";
                };

                r52_0a_ctcm_global: r52_0a_ctcm_global@20000 {
                        phandle = <0x2c>;
                        status = "okay";
                        compatible = "zephyr,memory-region", "xlnx,tcm";
                        reg = <0x0 0x20000 0x0 0x8000>;
                        zephyr,memory-region = "R52_0A_CTCM_GLOBAL";
                };

                gic_r52: interrupt-controller@e2000000 {
                        phandle = <0xd7>;
                        status = "okay";
                        reg = <0x0 0xe2000000 0x0 0x10000 0x0 0xe2100000 0x0 0x80000>;
                        interrupt-controller;
                        #interrupt-cells = <0x4>;
                        compatible = "arm,gic-v3", "arm,gic";
                };
        };

        reserved-memory {
                #size-cells = <0x2>;
                #address-cells = <0x2>;
                ranges;

                scmi_buffer: memory@20000000 {
                        phandle = <0x295>;
                        no-map;
                        reg = <0x0 0x20000000 0x0 0x20000>;
                };

                plm_reserved_memory: plm_reserved_memory@00000000 {
                        phandle = <0x29b>;
                        label = "plm_reserved_memory";
                        no-map;
                        reg = <0x0 0x0 0x0 0x1000000>;
                };

                tfa_reserved_memory: tfa_reserved_memory@1000000 {
                        phandle = <0x29c>;
                        label = "tfa_reserved_memory";
                        no-map;
                        reg = <0x0 0x1000000 0x0 0x600000>;
                };

                ddrboot: ddrboot@9800100 {
                        phandle = <0x2a3>;
                        reg = <0x0 0x9800100 0x0 0x5de00>;
                        compatible = "zephyr,memory-region";
                        zephyr,memory-region = "DDRBOOT";
                };

                trace_buffer: trace@985f000 {
                        phandle = <0x2a4>;
                        reg = <0x0 0x985f000 0x0 0x1000>;
                        compatible = "zephyr,memory-region";
                        zephyr,memory-region = "TRACE_BUFFER";
                        zephyr,memory-attr = <0x200000>;
                };

                rsctbl: rsctbl@9800000 {
                        phandle = <0x2a5>;
                        reg = <0x0 0x9800000 0x0 0x100>;
                        compatible = "zephyr,memory-region";
                        zephyr,memory-region = "RSCTBL";
                        zephyr,memory-attr = <0x200000>;
                };

                libmetal_elf: libmetal_elf@9968000 {
                        phandle = <0x2ac>;
                        label = "libmetal_elf";
                        no-map;
                        reg = <0x0 0x9968000 0x0 0x60000>;
                };

                libmetal_desc0: libmetal_desc0@99c8000 {
                        phandle = <0x2ad>;
                        label = "libmetal_desc0";
                        no-map;
                        reg = <0x0 0x99c8000 0x0 0x4000>;
                };

                libmetal_desc1: libmetal_desc1@99cc000 {
                        phandle = <0x2ae>;
                        label = "libmetal_desc1";
                        no-map;
                        reg = <0x0 0x99cc000 0x0 0x4000>;
                };

                libmetal_data: libmetal_data@99d0000 {
                        phandle = <0x2af>;
                        label = "libmetal_data";
                        no-map;
                        reg = <0x0 0x99d0000 0x0 0x40000>;
                };

                ipc_shm: ipc@9880000 {
                        phandle = <0x2b0>;
                        reg = <0x0 0x9880000 0x0 0x80000>;
                        compatible = "mmio-sram";
                        status = "okay";
                };
        };

        chosen {
                zephyr,ram-console = "/reserved-memory/trace@985f000";
                stdout-path = "serial0:115200n8";
                bootargs = "console=ttyAMA0,115200";
                zephyr,console = "serial0";
                zephyr,shell-uart = "serial0";
                zephyr,ipc_shm = "/reserved-memory/ipc@9880000";
                zephyr,sram = "/axi/r52_0a_atcm_global@0";
                zephyr,ipc = "/mbox_ipi_eb3b0000_eb3b1000";
        };

        mbox-consumer {
                compatible = "vnd,mbox-consumer";
                mboxes = <&ipi_2_nobuf_to_ipi_1_nobuf 0x0>,
                 <&ipi_2_nobuf_to_ipi_1_nobuf 0x1>;
                mbox-names = "tx", "rx";
        };

        mbox_ipi_eb3b0000_eb3b1000 {
                compatible = "zephyr,mbox-ipm";
                mbox-names = "tx", "rx";
                status = "okay";
                mboxes = <&ipi_2_nobuf_to_ipi_1_nobuf 0x0>,
                 <&ipi_2_nobuf_to_ipi_1_nobuf 0x1>;
        };

        NoC_C0_C1_ddr_memory: memory@100000 {
                phandle = <0x4>;
                compatible = "xlnx,axi-noc2-1.1";
                xlnx,ip-name = "axi_noc2";
                device_type = "memory";
                reg = <0x0 0x100000 0x0 0x7ff00000>;
                memory_type = "memory";
        };

        ps_wizard_0_ps11_0_ocm_ram_0_memory: memory@bbf00000 {
                phandle = <0xe>;
                compatible = "xlnx,ocm-ram-11.0", "mmio-sram";
                device_type = "memory";
                reg = <0x0 0xbbf00000 0x0 0x80000>;
        };

        ps_wizard_0_ps11_0_ocm_ram_1_memory: memory@bbf80000 {
                phandle = <0xf>;
                compatible = "xlnx,ocm-ram-11.0", "mmio-sram";
                device_type = "memory";
                reg = <0x0 0xbbf80000 0x0 0x80000>;
        };

        ps_wizard_0_ps11_0_ocm_ram_2_memory: memory@bbe00000 {
                phandle = <0x10>;
                compatible = "xlnx,ocm-ram-11.0", "mmio-sram";
                device_type = "memory";
                reg = <0x0 0xbbe00000 0x0 0x80000>;
        };

        ps_wizard_0_ps11_0_ocm_ram_3_memory: memory@bbe80000 {
                phandle = <0x11>;
                compatible = "xlnx,ocm-ram-11.0", "mmio-sram";
                device_type = "memory";
                reg = <0x0 0xbbe80000 0x0 0x80000>;
        };

        adma_ref_clk: adma_ref_clk {
                phandle = <0x1>;
                compatible = "fixed-clock";
                #clock-cells = <0x0>;
                clock-frequency = <0x1ad27480>;
        };

        can0_ref_clock: can0_ref_clock {
                phandle = <0x3>;
                compatible = "fixed-clock";
                #clock-cells = <0x0>;
                clock-frequency = <0x98961be>;
        };

        can1_ref_clock: can1_ref_clock {
                phandle = <0x5>;
                compatible = "fixed-clock";
                #clock-cells = <0x0>;
                clock-frequency = <0x98961be>;
        };

        can2_ref_clock: can2_ref_clock {
                phandle = <0x6>;
                compatible = "fixed-clock";
                #clock-cells = <0x0>;
                clock-frequency = <0x98961be>;
        };

        can3_ref_clock: can3_ref_clock {
                phandle = <0x7>;
                compatible = "fixed-clock";
                #clock-cells = <0x0>;
                clock-frequency = <0x98961be>;
        };

        i2c0_ref_clock: i2c0_ref_clock {
                phandle = <0x8>;
                compatible = "fixed-clock";
                #clock-cells = <0x0>;
                clock-frequency = <0x98961be>;
        };

        i2c1_ref_clock: i2c1_ref_clock {
                phandle = <0x9>;
                compatible = "fixed-clock";
                #clock-cells = <0x0>;
                clock-frequency = <0x98961be>;
        };

        i2c8_ref_clock: i2c8_ref_clock {
                phandle = <0xa>;
                compatible = "fixed-clock";
                #clock-cells = <0x0>;
                clock-frequency = <0x8f0cba9>;
        };

        ufshc_ref_clock: ufshc_ref_clock {
                phandle = <0xb>;
                compatible = "fixed-clock";
                #clock-cells = <0x0>;
                clock-frequency = <0x18cba80>;
        };

        __symbols__ {
                cpus_r52_0 = "/cpus";
                cortexr52_0 = "/cpus/cpu@0";
                timer = "/timer";
                amba = "/axi";
                adma0 = "/axi/dma-controller@ebd00000";
                adma1 = "/axi/dma-controller@ebd10000";
                adma2 = "/axi/dma-controller@ebd20000";
                adma3 = "/axi/dma-controller@ebd30000";
                adma4 = "/axi/dma-controller@ebd40000";
                adma5 = "/axi/dma-controller@ebd50000";
                adma6 = "/axi/dma-controller@ebd60000";
                adma7 = "/axi/dma-controller@ebd70000";
                can0 = "/axi/can@f19e0000";
                can1 = "/axi/can@f19f0000";
                can2 = "/axi/can@f1a00000";
                can3 = "/axi/can@f1a10000";
                gem0 = "/axi/ethernet@f1a60000";
                gem0_mac = "/axi/ethernet@f1a60000/ethernet_mac";
                gpio0 = "/axi/gpio@f1a50000";
                gpio0_bank0 = "/axi/gpio@f1a50000/gpio0_bank@0";
                gpio0_bank3 = "/axi/gpio@f1a50000/gpio0_bank@3";
                gpio0_bank4 = "/axi/gpio@f1a50000/gpio0_bank@4";
                gpio1 = "/axi/gpio@f1020000";
                gpio1_bank0 = "/axi/gpio@f1020000/gpio1_bank@0";
                gpio1_bank1 = "/axi/gpio@f1020000/gpio1_bank@1";
                gpio1_bank3 = "/axi/gpio@f1020000/gpio1_bank@3";
                gpio1_bank4 = "/axi/gpio@f1020000/gpio1_bank@4";
                gpio1_bank2 = "/axi/gpio@f1020000/gpio1_bank@2";
                gpio1_bank5 = "/axi/gpio@f1020000/gpio1_bank@5";
                i2c0 = "/axi/i2c@f1940000";
                i2c1 = "/axi/i2c@f1950000";
                i2c8 = "/axi/i2c@f1000000";
                rtc = "/axi/rtc@f12a0000";
                serial0 = "/axi/serial@f1920000";
                serial1 = "/axi/serial@f1930000";
                ttc0 = "/axi/timer@f1e60000";
                ttc0_timer0 = "/axi/timer@f1e60000/counter@0";
                ttc0_timer1 = "/axi/timer@f1e60000/counter@1";
                ttc0_timer2 = "/axi/timer@f1e60000/counter@2";
                ttc1 = "/axi/timer@f1e70000";
                ttc1_timer0 = "/axi/timer@f1e70000/counter@0";
                ttc1_timer1 = "/axi/timer@f1e70000/counter@1";
                ttc1_timer2 = "/axi/timer@f1e70000/counter@2";
                ttc2 = "/axi/timer@f1e80000";
                ttc2_timer0 = "/axi/timer@f1e80000/counter@0";
                ttc2_timer1 = "/axi/timer@f1e80000/counter@1";
                ttc2_timer2 = "/axi/timer@f1e80000/counter@2";
                ttc4 = "/axi/timer@f1ea0000";
                ttc4_timer0 = "/axi/timer@f1ea0000/counter@0";
                ttc4_timer1 = "/axi/timer@f1ea0000/counter@1";
                ttc4_timer2 = "/axi/timer@f1ea0000/counter@2";
                ttc5 = "/axi/timer@f1eb0000";
                ttc5_timer0 = "/axi/timer@f1eb0000/counter@0";
                ttc5_timer1 = "/axi/timer@f1eb0000/counter@1";
                ttc5_timer2 = "/axi/timer@f1eb0000/counter@2";
                ttc6 = "/axi/timer@f1ec0000";
                ttc6_timer0 = "/axi/timer@f1ec0000/counter@0";
                ttc6_timer1 = "/axi/timer@f1ec0000/counter@1";
                ttc6_timer2 = "/axi/timer@f1ec0000/counter@2";
                ttc7 = "/axi/timer@f1ed0000";
                ttc7_timer0 = "/axi/timer@f1ed0000/counter@0";
                ttc7_timer1 = "/axi/timer@f1ed0000/counter@1";
                ttc7_timer2 = "/axi/timer@f1ed0000/counter@2";
                ufshc = "/axi/ufs@f10b0000";
                ipi1 = "/axi/mailbox@eb340000";
                ipi_1_to_ipi_asu = "/axi/mailbox@eb340000/child@eb310000";
                ipi_1_to_ipi_0 = "/axi/mailbox@eb340000/child@eb330000";
                ipi_1_to_ipi_1 = "/axi/mailbox@eb340000/child@eb340000";
                ipi_1_to_ipi_1_nobuf = "/axi/mailbox@eb340000/child@eb3b0000";
                ipi_1_to_ipi_2 = "/axi/mailbox@eb340000/child@eb350000";
                ipi_1_to_ipi_2_nobuf = "/axi/mailbox@eb340000/child@eb3b1000";
                ipi_1_to_ipi_3 = "/axi/mailbox@eb340000/child@eb360000";
                ipi_1_to_ipi_3_nobuf = "/axi/mailbox@eb340000/child@eb3b2000";
                ipi_1_to_ipi_4 = "/axi/mailbox@eb340000/child@eb370000";
                ipi_1_to_ipi_4_nobuf = "/axi/mailbox@eb340000/child@eb3b3000";
                ipi_1_to_ipi_5 = "/axi/mailbox@eb340000/child@eb380000";
                ipi_1_to_ipi_5_nobuf = "/axi/mailbox@eb340000/child@eb3b4000";
                ipi_1_to_ipi_6 = "/axi/mailbox@eb340000/child@eb3a0000";
                ipi_1_to_ipi_6_nobuf = "/axi/mailbox@eb340000/child@eb3b5000";
                ipi_1_to_ipi_pmc = "/axi/mailbox@eb340000/child@eb320000";
                ipi_1_to_ipi_pmc_nobuf = "/axi/mailbox@eb340000/child@eb390000";
                ipi_nobuf2 = "/axi/mailbox@eb3b1000";
                ipi_2_nobuf_to_ipi_asu = "/axi/mailbox@eb3b1000/child@eb310000";
                ipi_2_nobuf_to_ipi_0 = "/axi/mailbox@eb3b1000/child@eb330000";
                ipi_2_nobuf_to_ipi_1 = "/axi/mailbox@eb3b1000/child@eb340000";
                ipi_2_nobuf_to_ipi_1_nobuf = "/axi/mailbox@eb3b1000/child@eb3b0000";
                ipi_2_nobuf_to_ipi_2 = "/axi/mailbox@eb3b1000/child@eb350000";
                ipi_2_nobuf_to_ipi_2_nobuf = "/axi/mailbox@eb3b1000/child@eb3b1000";
                ipi_2_nobuf_to_ipi_3 = "/axi/mailbox@eb3b1000/child@eb360000";
                ipi_2_nobuf_to_ipi_3_nobuf = "/axi/mailbox@eb3b1000/child@eb3b2000";
                ipi_2_nobuf_to_ipi_4 = "/axi/mailbox@eb3b1000/child@eb370000";
                ipi_2_nobuf_to_ipi_4_nobuf = "/axi/mailbox@eb3b1000/child@eb3b3000";
                ipi_2_nobuf_to_ipi_5 = "/axi/mailbox@eb3b1000/child@eb380000";
                ipi_2_nobuf_to_ipi_5_nobuf = "/axi/mailbox@eb3b1000/child@eb3b4000";
                ipi_2_nobuf_to_ipi_6 = "/axi/mailbox@eb3b1000/child@eb3a0000";
                ipi_2_nobuf_to_ipi_6_nobuf = "/axi/mailbox@eb3b1000/child@eb3b5000";
                ipi_2_nobuf_to_ipi_pmc = "/axi/mailbox@eb3b1000/child@eb320000";
                ipi_2_nobuf_to_ipi_pmc_nobuf = "/axi/mailbox@eb3b1000/child@eb390000";
                r52_0a_atcm_global = "/axi/r52_0a_atcm_global@0";
                r52_0a_btcm_global = "/axi/r52_0a_btcm_global@10000";
                r52_0a_ctcm_global = "/axi/r52_0a_ctcm_global@20000";
                gic_r52 = "/axi/interrupt-controller@e2000000";
                scmi_buffer = "/reserved-memory/memory@20000000";
                plm_reserved_memory = "/reserved-memory/plm_reserved_memory@00000000";
                tfa_reserved_memory = "/reserved-memory/tfa_reserved_memory@1000000";
                ddrboot = "/reserved-memory/ddrboot@9800100";
                trace_buffer = "/reserved-memory/trace@985f000";
                rsctbl = "/reserved-memory/rsctbl@9800000";
                libmetal_elf = "/reserved-memory/libmetal_elf@9968000";
                libmetal_desc0 = "/reserved-memory/libmetal_desc0@99c8000";
                libmetal_desc1 = "/reserved-memory/libmetal_desc1@99cc000";
                libmetal_data = "/reserved-memory/libmetal_data@99d0000";
                ipc_shm = "/reserved-memory/ipc@9880000";
                NoC_C0_C1_ddr_memory = "/memory@100000";
                ps_wizard_0_ps11_0_ocm_ram_0_memory = "/memory@bbf00000";
                ps_wizard_0_ps11_0_ocm_ram_1_memory = "/memory@bbf80000";
                ps_wizard_0_ps11_0_ocm_ram_2_memory = "/memory@bbe00000";
                ps_wizard_0_ps11_0_ocm_ram_3_memory = "/memory@bbe80000";
                adma_ref_clk = "/adma_ref_clk";
                can0_ref_clock = "/can0_ref_clock";
                can1_ref_clock = "/can1_ref_clock";
                can2_ref_clock = "/can2_ref_clock";
                can3_ref_clock = "/can3_ref_clock";
                i2c0_ref_clock = "/i2c0_ref_clock";
                i2c1_ref_clock = "/i2c1_ref_clock";
                i2c8_ref_clock = "/i2c8_ref_clock";
                ufshc_ref_clock = "/ufshc_ref_clock";
        };
};
